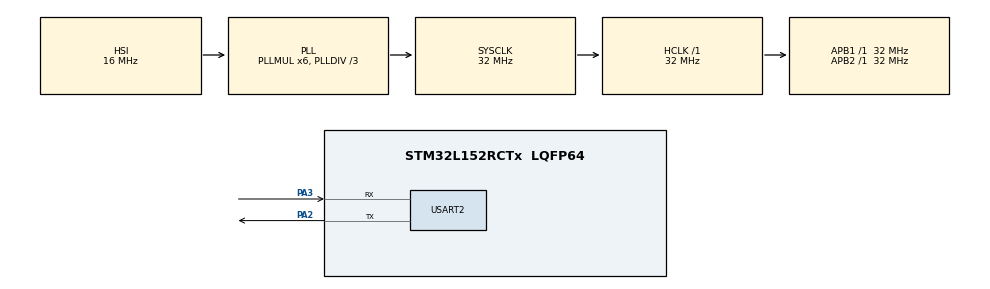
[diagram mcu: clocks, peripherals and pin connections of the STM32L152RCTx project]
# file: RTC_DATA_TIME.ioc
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Mcu.Family=STM32L1
Mcu.Name=STM32L152RCTx
Mcu.Package=LQFP64
NVIC.PriorityGroup=NVIC_PRIORITYGROUP_0
PA13.Mode=Serial_Wire
PA13.Signal=SYS_JTMS-SWDIO
PA14.Mode=Serial_Wire
PA14.Signal=SYS_JTCK-SWCLK
PA2.Mode=Asynchronous
PA2.Signal=USART2_TX
PA3.Mode=Asynchronous
PA3.Signal=USART2_RX
PC14-OSC32_IN.Mode=LSE-External-Oscillator
PC14-OSC32_IN.Signal=RCC_OSC32_IN
PC15-OSC32_OUT.Mode=LSE-External-Oscillator
PC15-OSC32_OUT.Signal=RCC_OSC32_OUT
PH0-OSC_IN.Mode=HSE-External-Oscillator
PH0-OSC_IN.Signal=RCC_OSC_IN
PH1-OSC_OUT.Mode=HSE-External-Oscillator
PH1-OSC_OUT.Signal=RCC_OSC_OUT
ProjectManager.HeapSize=0x200
ProjectManager.StackSize=0x400
ProjectManager.TargetToolchain=STM32CubeIDE
RCC.48MHZClocksFreq_Value=48000000
RCC.AHBFreq_Value=32000000
RCC.APB1Freq_Value=32000000
RCC.APB1TimFreq_Value=32000000
RCC.APB2Freq_Value=32000000
RCC.APB2TimFreq_Value=32000000
RCC.HCLKFreq_Value=32000000
RCC.HSE_VALUE=8000000
RCC.HSI_VALUE=16000000
RCC.MSI_VALUE=2097000
RCC.PLLDIV=RCC_PLL_DIV3
RCC.PLLMUL=RCC_PLL_MUL6
RCC.RTCClockSelectionVirtual=RCC_RTCCLKSOURCE_LSE
RCC.SYSCLKFreq_VALUE=32000000
RCC.SYSCLKSource=RCC_SYSCLKSOURCE_PLLCLK
RCC.USBOutput=48000000
RCC.VCOOutputFreq_Value=96000000
RTC.Date=3
RTC.WeekDay=RTC_WEEKDAY_FRIDAY
RTC.Year=23
USART2.VirtualMode=VM_ASYNC
VP_RTC_VS_RTC_Activate.Mode=RTC_Enabled
VP_RTC_VS_RTC_Calendar.Mode=RTC_Calendar
board=STM32L152C-DISCO

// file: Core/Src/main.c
/* USER CODE BEGIN Header */
/**
  ******************************************************************************
  * @file           : main.c
  * @brief          : Main program body
  ******************************************************************************
  * @attention
  *
  * Copyright (c) 2023 STMicroelectronics.
  * All rights reserved.
  *
  * This software is licensed under terms that can be found in the LICENSE file
  * in the root directory of this software component.
  * If no LICENSE file comes with this software, it is provided AS-IS.
  *
  ******************************************************************************
  */
/* USER CODE END Header */
#include "main.h"

/* USER CODE BEGIN Includes */
#include <stdio.h>
#include <string.h>

/* USER CODE END Includes */

/* USER CODE BEGIN PTD */
char time[30];
char date[30];
RTC_TimeTypeDef sTime;
RTC_DateTypeDef sDate;

/* USER CODE END PTD */

RTC_HandleTypeDef hrtc;

UART_HandleTypeDef huart2;

void SystemClock_Config(void);
static void MX_GPIO_Init(void);
static void MX_RTC_Init(void);
static void MX_USART2_UART_Init(void);

int main(void)
{

  /* MCU Configuration--------------------------------------------------------*/

  /* Reset of all peripherals, Initializes the Flash interface and the Systick. */
  HAL_Init();

  /* Configure the system clock */
  SystemClock_Config();

  /* Initialize all configured peripherals */
  MX_GPIO_Init();
  MX_RTC_Init();
  MX_USART2_UART_Init();

  /* Infinite loop */
  while (1)
  {

    /* USER CODE BEGIN 3 */
	  HAL_RTC_GetTime(&hrtc, &sTime, RTC_FORMAT_BIN);
	  HAL_RTC_GetDate(&hrtc, &sDate, RTC_FORMAT_BIN);

	  sprintf(date,"Date: %02d.%02d.%02d\t",sDate.Date,sDate.Month,2000+sDate.Year);
	  sprintf(time,"Time: %02d.%02d.%02d\r\n",sTime.Hours,sTime.Minutes,sTime.Seconds);

	  HAL_UART_Transmit(&huart2,date, sizeof(date), 300);
	  HAL_UART_Transmit(&huart2,time, sizeof(time), 300);
	  HAL_Delay(1000);

  }
  /* USER CODE END 3 */
}

void SystemClock_Config(void)
{
  RCC_OscInitTypeDef RCC_OscInitStruct = {0};
  RCC_ClkInitTypeDef RCC_ClkInitStruct = {0};
  RCC_PeriphCLKInitTypeDef PeriphClkInit = {0};

  /** Configure the main internal regulator output voltage
  */
  __HAL_PWR_VOLTAGESCALING_CONFIG(PWR_REGULATOR_VOLTAGE_SCALE1);

  /** Initializes the RCC Oscillators according to the specified parameters
  * in the RCC_OscInitTypeDef structure.
  */
  RCC_OscInitStruct.OscillatorType = RCC_OSCILLATORTYPE_HSI|RCC_OSCILLATORTYPE_LSE;
  RCC_OscInitStruct.LSEState = RCC_LSE_ON;
  RCC_OscInitStruct.HSIState = RCC_HSI_ON;
  RCC_OscInitStruct.HSICalibrationValue = RCC_HSICALIBRATION_DEFAULT;
  RCC_OscInitStruct.PLL.PLLState = RCC_PLL_ON;
  RCC_OscInitStruct.PLL.PLLSource = RCC_PLLSOURCE_HSI;
  RCC_OscInitStruct.PLL.PLLMUL = RCC_PLL_MUL6;
  RCC_OscInitStruct.PLL.PLLDIV = RCC_PLL_DIV3;
  if (HAL_RCC_OscConfig(&RCC_OscInitStruct) != HAL_OK)
  {
    Error_Handler();
  }

  /** Initializes the CPU, AHB and APB buses clocks
  */
  RCC_ClkInitStruct.ClockType = RCC_CLOCKTYPE_HCLK|RCC_CLOCKTYPE_SYSCLK
                              |RCC_CLOCKTYPE_PCLK1|RCC_CLOCKTYPE_PCLK2;
  RCC_ClkInitStruct.SYSCLKSource = RCC_SYSCLKSOURCE_PLLCLK;
  RCC_ClkInitStruct.AHBCLKDivider = RCC_SYSCLK_DIV1;
  RCC_ClkInitStruct.APB1CLKDivider = RCC_HCLK_DIV1;
  RCC_ClkInitStruct.APB2CLKDivider = RCC_HCLK_DIV1;

  if (HAL_RCC_ClockConfig(&RCC_ClkInitStruct, FLASH_LATENCY_1) != HAL_OK)
  {
    Error_Handler();
  }
  PeriphClkInit.PeriphClockSelection = RCC_PERIPHCLK_RTC;
  PeriphClkInit.RTCClockSelection = RCC_RTCCLKSOURCE_LSE;
  if (HAL_RCCEx_PeriphCLKConfig(&PeriphClkInit) != HAL_OK)
  {
    Error_Handler();
  }
}

static void MX_RTC_Init(void)
{

  RTC_TimeTypeDef sTime = {0};
  RTC_DateTypeDef sDate = {0};

  /** Initialize RTC Only
  */
  hrtc.Instance = RTC;
  hrtc.Init.HourFormat = RTC_HOURFORMAT_24;
  hrtc.Init.AsynchPrediv = 127;
  hrtc.Init.SynchPrediv = 255;
  hrtc.Init.OutPut = RTC_OUTPUT_DISABLE;
  hrtc.Init.OutPutPolarity = RTC_OUTPUT_POLARITY_HIGH;
  hrtc.Init.OutPutType = RTC_OUTPUT_TYPE_OPENDRAIN;
  if (HAL_RTC_Init(&hrtc) != HAL_OK)
  {
    Error_Handler();
  }

  /** Initialize RTC and set the Time and Date
  */
  sTime.Hours = 0x10;
  sTime.Minutes = 0x20;
  sTime.Seconds = 0x30;
  sTime.DayLightSaving = RTC_DAYLIGHTSAVING_NONE;
  sTime.StoreOperation = RTC_STOREOPERATION_RESET;
  if (HAL_RTC_SetTime(&hrtc, &sTime, RTC_FORMAT_BCD) != HAL_OK)
  {
    Error_Handler();
  }
  sDate.WeekDay = RTC_WEEKDAY_FRIDAY;
  sDate.Month = RTC_MONTH_JANUARY;
  sDate.Date = 0x3;
  sDate.Year = 0x23;

  if (HAL_RTC_SetDate(&hrtc, &sDate, RTC_FORMAT_BCD) != HAL_OK)
  {
    Error_Handler();
  }

}

static void MX_USART2_UART_Init(void)
{

  huart2.Instance = USART2;
  huart2.Init.BaudRate = 115200;
  huart2.Init.WordLength = UART_WORDLENGTH_8B;
  huart2.Init.StopBits = UART_STOPBITS_1;
  huart2.Init.Parity = UART_PARITY_NONE;
  huart2.Init.Mode = UART_MODE_TX_RX;
  huart2.Init.HwFlowCtl = UART_HWCONTROL_NONE;
  huart2.Init.OverSampling = UART_OVERSAMPLING_16;
  if (HAL_UART_Init(&huart2) != HAL_OK)
  {
    Error_Handler();
  }

}

static void MX_GPIO_Init(void)
{

  /* GPIO Ports Clock Enable */
  __HAL_RCC_GPIOC_CLK_ENABLE();
  __HAL_RCC_GPIOH_CLK_ENABLE();
  __HAL_RCC_GPIOA_CLK_ENABLE();

}

void Error_Handler(void)
{
  __disable_irq();
  while (1)
  {
  }
}
